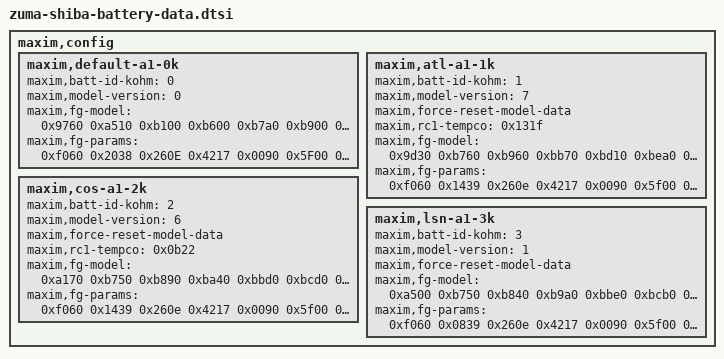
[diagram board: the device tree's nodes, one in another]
// SPDX-License-Identifier: GPL-2.0-only
/*
 * Battery device tree entries
 *
 * Copyright 2022 Google LLC
 *
 */

maxim,config {

	/* R4_p1_gen.ini, 2021-01-21, b/174787673, generic model */
	maxim,default-a1-0k {
		maxim,batt-id-kohm = <0>;
		maxim,model-version = <0>;
		maxim,fg-model = /bits/ 16 <
			0x9760 0xa510 0xb100 0xb600 0xb7a0 0xb900 0xba70 0xbc70
			0xbde0 0xbfc0 0xc250 0xc510 0xc990 0xcea0 0xd040 0xd750
			0x0060 0x0120 0x0200 0x0710 0x0e80 0x0df0 0x1430 0x1bd0
			0x1520 0x0d70 0x0950 0x08e0 0x0800 0x0780 0x06b0 0x01e0
			0x0100 0x0100 0x0100 0x0100 0x0100 0x0100 0x0100 0x0100
			0x0100 0x0100 0x0100 0x0100 0x0100 0x0100 0x0100 0x0100
		>;
		maxim,fg-params = /bits/ 16 <
			/* 0x0036 */	0xf060	/* IAvgEmpty */
			/* 0x002a */	0x2038	/* RelaxCFG */
			/* 0x0028 */	0x260E	/* LearnCFG */
			/* 0x001D */	0x4217	/* Config */
			/* 0x00BB */	0x0090	/* Config2 */
			/* 0x0013 */	0x5F00	/* FullSOCthr */
			/* 0x0035 */	0x0994	/* FullCAPRep */
			/* 0x0018 */	0x0994	/* DesignCap */
			/* 0x0046 */	0x0c80	/* dPacc */
			/* 0x0045 */	0x0099	/* dQacc */
			/* 0x0023 */	0x0994	/* FullCAPNom */
			/* 0x003A */	0xA561	/* V_empty */
			/* 0x0012 */	0x1100	/* QResidual00 */
			/* 0x0022 */	0x0800	/* QResidual10 */
			/* 0x0032 */	0x0301	/* QResidual20 */
			/* 0x0042 */	0x0302	/* QResidual30 */
			/* 0x0038 */	0x0700	/* RCOMP0 */
			/* 0x0039 */	0x223E	/* TempCo */
			/* 0x001E */	0x0310	/* ICHGTerm */
			/* 0x002C */	0xED51	/* TGain */
			/* 0x002D */	0x1EBA	/* TOff */
			/* 0x00B9 */	0x0014	/* Curve */
			/* 0x002B */	0x3870	/* MiscCFG */
			/* 0x0004 */	0x0000	/* AtRate */
			/* 0x0049 */	0x2241	/* convgcfg */
			/* 0x0029 */	0xc623	/* FilterCFG */
			/* 0x003c */	0x2D00	/* TaskPeriod */
		>;
	};

	/* SB3_ATL_3347_20240405_BC59_RC2.ini.txt, b/335071363#comment2 */
	maxim,atl-a1-1k {
		maxim,batt-id-kohm = <1>;
		maxim,model-version = <7>;
		maxim,force-reset-model-data;
		maxim,rc1-tempco = /bits/ 16 <0x131f>;
		maxim,fg-model = /bits/ 16 <
			0x9d30 0xb760 0xb960 0xbb70 0xbd10 0xbea0 0xbff0 0xc290
			0xc4a0 0xc710 0xcb30 0xcd60 0xd300 0xd650 0xd970 0xdf40
			0x0100 0x0f00 0x0e00 0x1300 0x1600 0x16b0 0x0a30 0x0be0
			0x05f0 0x07d0 0x08f0 0x05e0 0x06d0 0x08f0 0x02f0 0x02f0
			0x0200 0x0200 0x0200 0x0200 0x0200 0x0200 0x0200 0x0200
			0x0200 0x0200 0x0200 0x0200 0x0200 0x0200 0x0200 0x0200
		>;
		maxim,fg-params = /bits/ 16 <
			/* 0x0036 */	0xf060	/* IAvgEmpty */
			/* 0x002a */	0x1439	/* RelaxCFG */
			/* 0x0028 */	0x260e	/* LearnCFG */
			/* 0x001D */	0x4217	/* Config */
			/* 0x00BB */	0x0090	/* Config2 */
			/* 0x0013 */	0x5f00	/* FullSOCthr */
			/* 0x0035 */	0x08E3	/* FullCAPRep */
			/* 0x0018 */	0x08E3	/* DesignCap */
			/* 0x0046 */	0x3200	/* dPacc */
			/* 0x0045 */	0x0238	/* dQacc */
			/* 0x0023 */	0x08E3	/* FullCAPNom */
			/* 0x003A */	0xa561	/* V_empty */
			/* 0x0012 */	0x2080	/* QResidual00 */
			/* 0x0022 */	0x0e80	/* QResidual10 */
			/* 0x0032 */	0x0580	/* QResidual20 */
			/* 0x0042 */	0x0400	/* QResidual30 */
			/* 0x0038 */	0x03b0	/* RCOMP0 */
			/* 0x0039 */	0x1402	/* TempCo */
			/* 0x001E */	0x059B	/* ICHGTerm */
			/* 0x002C */	0xED51	/* TGain */
			/* 0x002D */	0x1EBA	/* TOff */
			/* 0x00B9 */	0x0014	/* Curve */
			/* 0x002B */	0x6070	/* MiscCFG */
			/* 0x0004 */	0x1900	/* AtRate */
			/* 0x0049 */	0x2241	/* convgcfg */
			/* 0x0029 */	0x0613	/* FilterCFG */
			/* 0x003c */	0x2D00	/* TaskPeriod */
		>;
	};

        /* SB3_COS_3348_20240405_BC59_RC2.ini.txt, b/335071363#comment2 */
	maxim,cos-a1-2k {
		maxim,batt-id-kohm = <2>;
		maxim,model-version = <6>;
		maxim,force-reset-model-data;
		maxim,rc1-tempco = /bits/ 16 <0x0b22>;
		maxim,fg-model = /bits/ 16 <
                        0xa170 0xb750 0xb890 0xba40 0xbbd0 0xbcd0 0xbf00 0xc080
                        0xc390 0xc7b0 0xcae0 0xce10 0xd190 0xd480 0xd780 0xdda0
                        0x0140 0x1420 0x0d20 0x0f10 0x1110 0x1340 0x0f10 0x0d30
                        0x0660 0x07a0 0x07c0 0x0700 0x06c0 0x06f0 0x0650 0x0650
                        0x0200 0x0200 0x0200 0x0200 0x0200 0x0200 0x0200 0x0200
                        0x0200 0x0200 0x0200 0x0200 0x0200 0x0200 0x0200 0x0200
		>;
		maxim,fg-params = /bits/ 16 <
			/* 0x0036 */	0xf060	/* IAvgEmpty */
			/* 0x002a */	0x1439	/* RelaxCFG */
			/* 0x0028 */	0x260e	/* LearnCFG */
			/* 0x001D */	0x4217	/* Config */
			/* 0x00BB */	0x0090	/* Config2 */
			/* 0x0013 */	0x5f00	/* FullSOCthr */
			/* 0x0035 */	0x08E3	/* FullCAPRep */
			/* 0x0018 */	0x08E3	/* DesignCap */
			/* 0x0046 */	0x3200	/* dPacc */
			/* 0x0045 */	0x0238	/* dQacc */
			/* 0x0023 */	0x08E3	/* FullCAPNom */
			/* 0x003A */	0xa561	/* V_empty */
			/* 0x0012 */	0x1900	/* QResidual00 */
			/* 0x0022 */	0x0b80	/* QResidual10 */
			/* 0x0032 */	0x0500	/* QResidual20 */
			/* 0x0042 */	0x0480	/* QResidual30 */
			/* 0x0038 */	0x03b0	/* RCOMP0 */
			/* 0x0039 */	0x1602	/* TempCo */
			/* 0x001E */	0x059B	/* ICHGTerm */
			/* 0x002C */	0xED51	/* TGain */
			/* 0x002D */	0x1EBA	/* TOff */
			/* 0x00B9 */	0x0014	/* Curve */
			/* 0x002B */	0x6070	/* MiscCFG */
			/* 0x0004 */	0x1900	/* AtRate */
			/* 0x0049 */	0x2241	/* convgcfg */
			/* 0x0029 */	0x0613	/* FilterCFG */
			/* 0x003c */	0x2D00	/* TaskPeriod */
		>;
	};

	/* LSN: SB3_LSN_placeholder_BC59O6_RC2.ini.txt, 2022-03-04, b/238972338#comment2 */
	maxim,lsn-a1-3k {
		maxim,batt-id-kohm = <3>;
		maxim,model-version = <1>;
		maxim,force-reset-model-data;
		maxim,fg-model = /bits/ 16 <
                        0xa500 0xb750 0xb840 0xb9a0 0xbbe0 0xbcb0 0xbe30 0xbfb0
                        0xc0e0 0xc3f0 0xc760 0xca40 0xcd20 0xd160 0xd500 0xdc40
                        0x0120 0x12a0 0x0e80 0x0ef0 0x1450 0x1ae0 0x12f0 0x10f0
                        0x0a10 0x0790 0x07e0 0x0800 0x0680 0x0700 0x0660 0x0660
                        0x0200 0x0200 0x0200 0x0200 0x0200 0x0200 0x0200 0x0200
                        0x0200 0x0200 0x0200 0x0200 0x0200 0x0200 0x0200 0x0200
		>;
		maxim,fg-params = /bits/ 16 <
			/* 0x0036 */	0xf060	/* IAvgEmpty */
			/* 0x002a */	0x0839	/* RelaxCFG */
			/* 0x0028 */	0x260e	/* LearnCFG */
			/* 0x001D */	0x4217	/* Config */
			/* 0x00BB */	0x0090	/* Config2 */
			/* 0x0013 */	0x5f00	/* FullSOCthr */
			/* 0x0035 */	0x08E3	/* FullCAPRep */
			/* 0x0018 */	0x08E3	/* DesignCap */
			/* 0x0046 */	0x3200	/* dPacc */
			/* 0x0045 */	0x0238	/* dQacc */
			/* 0x0023 */	0x08E3	/* FullCAPNom */
			/* 0x003A */	0xa561	/* V_empty */
			/* 0x0012 */	0x2d00	/* QResidual00 */
			/* 0x0022 */	0x1400	/* QResidual10 */
			/* 0x0032 */	0x0780	/* QResidual20 */
			/* 0x0042 */	0x0680	/* QResidual30 */
			/* 0x0038 */	0x0760	/* RCOMP0 */
			/* 0x0039 */	0x0c02	/* TempCo */
			/* 0x001E */	0x059B	/* ICHGTerm */
			/* 0x002C */	0xED51	/* TGain */
			/* 0x002D */	0x1EBA	/* TOff */
			/* 0x00B9 */	0x0014	/* Curve */
			/* 0x002B */	0x3870	/* MiscCFG */
			/* 0x0004 */	0x1900	/* AtRate */
			/* 0x0049 */	0x2241	/* convgcfg */
			/* 0x0029 */	0x0623	/* FilterCFG */
			/* 0x003c */	0x2D00	/* TaskPeriod */
		>;
	};
};
